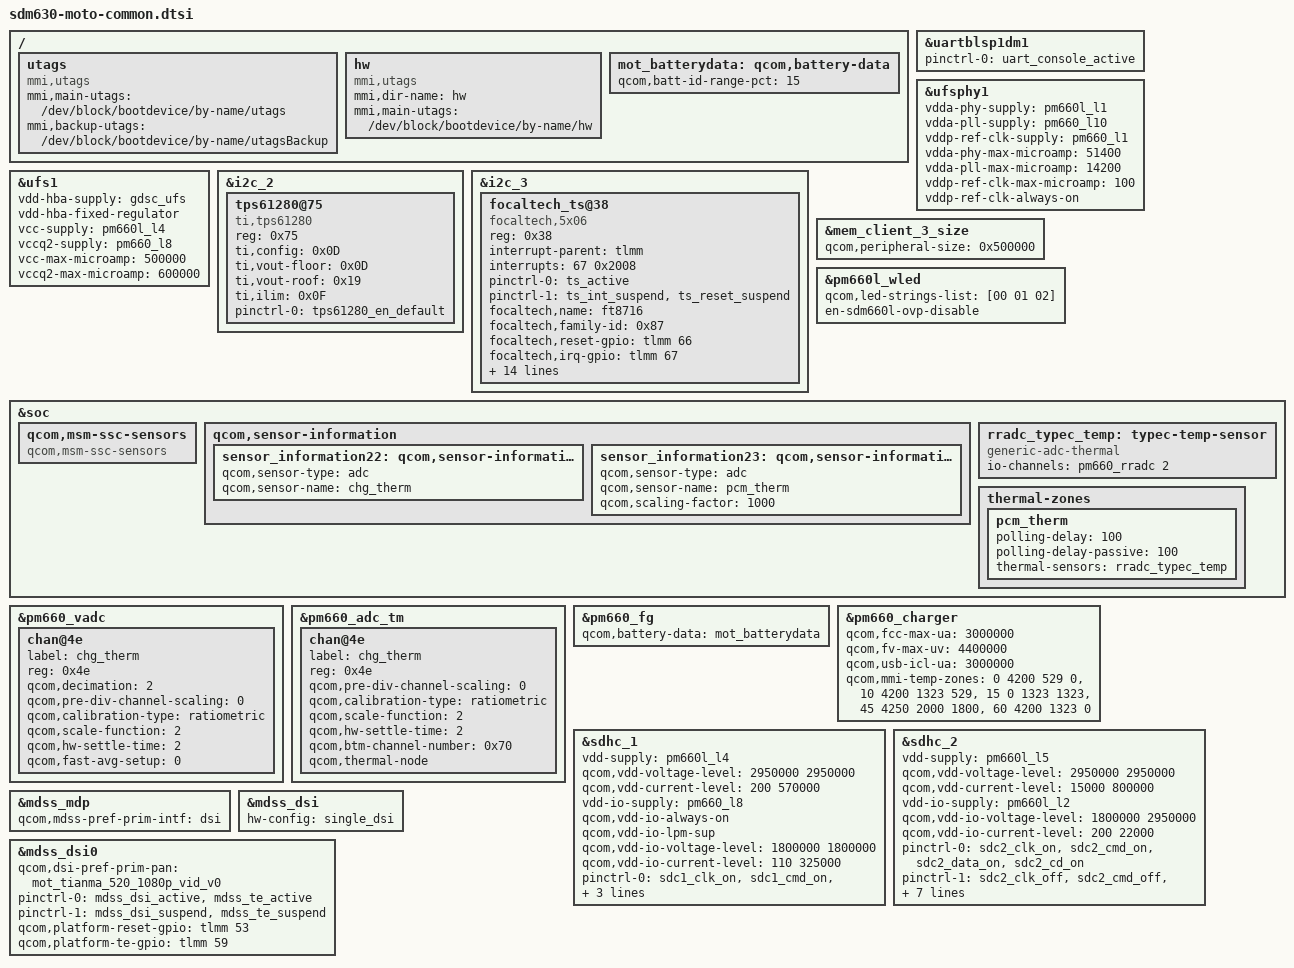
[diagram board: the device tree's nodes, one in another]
/* Copyright (c) 2016, Motorola Mobility Inc. All rights reserved.
 *
 * This program is free software; you can redistribute it and/or modify
 * it under the terms of the GNU General Public License version 2 and
 * only version 2 as published by the Free Software Foundation.
 *
 * This program is distributed in the hope that it will be useful,
 * but WITHOUT ANY WARRANTY; without even the implied warranty of
 * MERCHANTABILITY or FITNESS FOR A PARTICULAR PURPOSE.  See the
 * GNU General Public License for more details.
 */

#include "sdm660-pinctrl.dtsi"
#include "sdm660-moto-pinctrl.dtsi"
#include "carrier-channel-ids.dtsi"
#include "dsi-panel-mot-dummy-qhd-video.dtsi"
#include "dsi-panel-mot-tianma-520-1080p-vid.dtsi"
#include "dsi-panel-mot-boe-520-1080p-vid.dtsi"
#include "sdm660-moto-audio.dtsi"
#include "sdm660-moto-fps.dtsi"

/ {
	utags {
		compatible = "mmi,utags";
		mmi,main-utags = "/dev/block/bootdevice/by-name/utags";
		mmi,backup-utags = "/dev/block/bootdevice/by-name/utagsBackup";
	};

	hw {
		compatible = "mmi,utags";
		mmi,dir-name = "hw";
		mmi,main-utags = "/dev/block/bootdevice/by-name/hw";
	};

	mot_batterydata: qcom,battery-data {
		qcom,batt-id-range-pct = <15>;
		#include "fg-gen3-batterydata-hx40sunwoda-3000mah.dtsi"
	};
};

&uartblsp1dm1 {
	status = "ok";
	pinctrl-names = "default";
	pinctrl-0 = <&uart_console_active>;
};

&ufsphy1 {
	vdda-phy-supply = <&pm660l_l1>;
	vdda-pll-supply = <&pm660_l10>;
	vddp-ref-clk-supply = <&pm660_l1>;
	vdda-phy-max-microamp = <51400>;
	vdda-pll-max-microamp = <14200>;
	vddp-ref-clk-max-microamp = <100>;
	vddp-ref-clk-always-on;
	status = "ok";
};

&ufs1 {
	vdd-hba-supply = <&gdsc_ufs>;
	vdd-hba-fixed-regulator;
	vcc-supply = <&pm660l_l4>;
	vccq2-supply = <&pm660_l8>;
	vcc-max-microamp = <500000>;
	vccq2-max-microamp = <600000>;
	status = "ok";
};

&i2c_2 { /* BLSP1 CAP SENSOR */
	status = "okay";
	tps61280@75 {
		compatible = "ti,tps61280";
		reg = <0x75>;
		ti,config = <0x0D>;
		ti,vout-floor = <0x0D>;
		ti,vout-roof = <0x19>;
		ti,ilim = <0x0F>;
		pinctrl-names = "default";
		pinctrl-0 = <&tps61280_en_default>;
	};
};

&i2c_3 { /* BLSP1 QUP3 */
	status = "okay";
	focaltech_ts@38 {
		compatible = "focaltech,5x06";
		reg = <0x38>;
		interrupt-parent = <&tlmm>;
		interrupts = <67 0x2008>;
		pinctrl-names = "pmx_ts_active", "pmx_ts_suspend";
		pinctrl-0 = <&ts_active>;
		pinctrl-1 = <&ts_int_suspend &ts_reset_suspend>;
		focaltech,name = "ft8716";
		focaltech,family-id = <0x87>;
		focaltech,reset-gpio = <&tlmm 66 0x00>;
		focaltech,irq-gpio = <&tlmm 67 0x2008>;
		focaltech,display-coords = <0 0 1080 1920>;
		focaltech,panel-coords = <0 0 1080 1920>;
		focaltech,i2c-pull-up;
		focaltech,group-id = <1>;
		focaltech,hard-reset-delay-ms = <20>;
		focaltech,soft-reset-delay-ms = <200>;
		focaltech,num-max-touches = <10>;
		focaltech,fw-delay-aa-ms = <2>;
		focaltech,fw-delay-55-ms = <2>;
		focaltech,fw-upgrade-id1 = <0x87>;
		focaltech,fw-upgrade-id2 = <0xA6>;
		focaltech,fw-delay-readid-ms = <20>;
		focaltech,fw-delay-era-flsh-ms = <2000>;
		focaltech,resume-in-workqueue;
	};
};

&mem_client_3_size {
	qcom,peripheral-size = <0x500000>;
};

&pm660l_wled {
	qcom,led-strings-list = [01 02];
};

&soc {
	qcom,msm-ssc-sensors {
		compatible = "qcom,msm-ssc-sensors";
	};
	qcom,sensor-information {
		sensor_information22: qcom,sensor-information-22 {
			qcom,sensor-type =  "adc";
			qcom,sensor-name = "chg_therm";
		};
		sensor_information23: qcom,sensor-information-23 {
			qcom,sensor-type =  "adc";
			qcom,sensor-name = "pcm_therm";
			qcom,scaling-factor = <1000>;
		};
	};

	rradc_typec_temp: typec-temp-sensor {
		compatible = "generic-adc-thermal";
		#thermal-sensor-cells = <0>;
		io-channels = <&pm660_rradc 2>;
		io-channel-names = "sensor-channel";
	};

	thermal-zones {
		pcm_therm {
			polling-delay = <100>; /* milliseconds */
			polling-delay-passive = <100>; /* milliseconds */
			thermal-sensors = <&rradc_typec_temp>;
		};
	};
};

&pm660_vadc {
	chan@4e {
		label = "chg_therm";
		reg = <0x4e>;
		qcom,decimation = <2>;
		qcom,pre-div-channel-scaling = <0>;
		qcom,calibration-type = "ratiometric";
		qcom,scale-function = <2>;
		qcom,hw-settle-time = <2>;
		qcom,fast-avg-setup = <0>;
	};
};

&pm660_adc_tm {
	chan@4e {
		label = "chg_therm";
		reg = <0x4e>;
		qcom,pre-div-channel-scaling = <0>;
		qcom,calibration-type = "ratiometric";
		qcom,scale-function = <2>;
		qcom,hw-settle-time = <2>;
		qcom,btm-channel-number = <0x70>;
		qcom,thermal-node;
	};
};


&pm660_fg {
	qcom,battery-data = <&mot_batterydata>;
};

&pm660_charger {
	qcom,fcc-max-ua = <3000000>;
	qcom,fv-max-uv = <4400000>;
	qcom,usb-icl-ua = <3000000>;
	qcom,mmi-temp-zones = <0 4200 529 0>,
				<10 4200 1323 529>,
				<15 0 1323 1323>,
				<45 4250 2000 1800>,
				<60 4200 1323 0>;
};

&sdhc_1 {
	/* device core power supply */
	vdd-supply = <&pm660l_l4>;
	qcom,vdd-voltage-level = <2950000 2950000>;
	qcom,vdd-current-level = <200 570000>;

	/* device communication power supply */
	vdd-io-supply = <&pm660_l8>;
	qcom,vdd-io-always-on;
	qcom,vdd-io-lpm-sup;
	qcom,vdd-io-voltage-level = <1800000 1800000>;
	qcom,vdd-io-current-level = <110 325000>;

	pinctrl-names = "active", "sleep";
	pinctrl-0 = <&sdc1_clk_on &sdc1_cmd_on &sdc1_data_on &sdc1_rclk_on>;
	pinctrl-1 = <&sdc1_clk_off &sdc1_cmd_off &sdc1_data_off &sdc1_rclk_off>;

	status = "ok";
};

&sdhc_2 {
	/* device core power supply */
	vdd-supply = <&pm660l_l5>;
	qcom,vdd-voltage-level = <2950000 2950000>;
	qcom,vdd-current-level = <15000 800000>;

	/* device communication power supply */
	vdd-io-supply = <&pm660l_l2>;
	qcom,vdd-io-voltage-level = <1800000 2950000>;
	qcom,vdd-io-current-level = <200 22000>;

	pinctrl-names = "active", "sleep";
	pinctrl-0 = <&sdc2_clk_on &sdc2_cmd_on &sdc2_data_on &sdc2_cd_on>;
	pinctrl-1 = <&sdc2_clk_off &sdc2_cmd_off &sdc2_data_off &sdc2_cd_off>;

	#address-cells = <0>;
	interrupt-parent = <&sdhc_2>;
	interrupts = <0 1 2>;
	#interrupt-cells = <1>;
	interrupt-map-mask = <0xffffffff>;
	interrupt-map = <0 &intc 0 0 125 0
			1 &intc 0 0 221 0
			2 &tlmm 54 0>;
	interrupt-names = "hc_irq", "pwr_irq", "status_irq";
	cd-gpios = <&tlmm 54 0x0>;

	status = "ok";
};

&mdss_mdp {
	qcom,mdss-pref-prim-intf = "dsi";
};

&mdss_dsi {
	hw-config = "single_dsi";
};

&mdss_dsi0 {
	qcom,dsi-pref-prim-pan = <&mot_tianma_520_1080p_vid_v0>;
	pinctrl-names = "mdss_default", "mdss_sleep";
	pinctrl-0 = <&mdss_dsi_active &mdss_te_active>;
	pinctrl-1 = <&mdss_dsi_suspend &mdss_te_suspend>;
	qcom,platform-reset-gpio = <&tlmm 53 0>;
	qcom,platform-te-gpio = <&tlmm 59 0>;
};

&pm660l_wled {
	en-sdm660l-ovp-disable;
	qcom,led-strings-list = [00 01 02];
};
